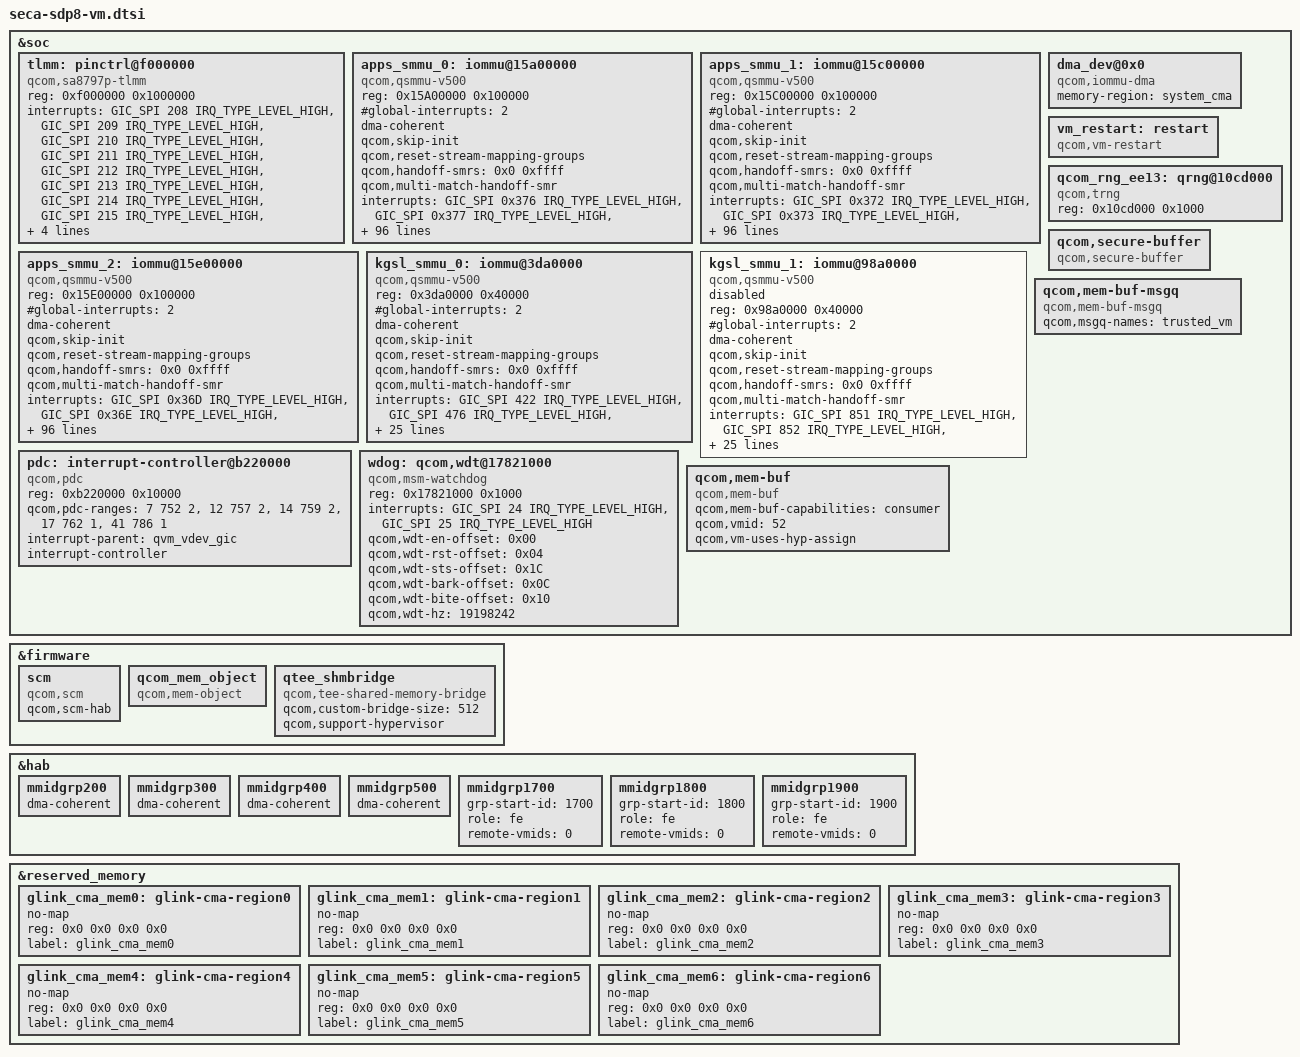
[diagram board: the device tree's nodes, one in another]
// SPDX-License-Identifier: BSD-3-Clause
/*
 * Copyright (c) Qualcomm Technologies, Inc. and/or its subsidiaries.
 */

#include "sdp8-quin-vm-common.dtsi"

&soc {
	tlmm: pinctrl@f000000 {
		compatible = "qcom,sa8797p-tlmm";
		reg = <0xf000000 0x1000000>;
		interrupts = <GIC_SPI 208 IRQ_TYPE_LEVEL_HIGH>,
			<GIC_SPI 209 IRQ_TYPE_LEVEL_HIGH>,
			<GIC_SPI 210 IRQ_TYPE_LEVEL_HIGH>,
			<GIC_SPI 211 IRQ_TYPE_LEVEL_HIGH>,
			<GIC_SPI 212 IRQ_TYPE_LEVEL_HIGH>,
			<GIC_SPI 213 IRQ_TYPE_LEVEL_HIGH>,
			<GIC_SPI 214 IRQ_TYPE_LEVEL_HIGH>,
			<GIC_SPI 215 IRQ_TYPE_LEVEL_HIGH>,
			<GIC_SPI 216 IRQ_TYPE_LEVEL_HIGH>;
		gpio-controller;
		qcom,dirconn-list = <50 GPIO_ACTIVE_HIGH>;
		#gpio-cells = <2>;
		interrupt-controller;
		#interrupt-cells = <2>;
		status = "ok";
	};

	apps_smmu_0: iommu@15a00000 {
		compatible = "qcom,qsmmu-v500";
		reg = <0x15A00000 0x100000>;
		reg-names = "base";
		#iommu-cells = <2>;
		#global-interrupts = <2>;
		dma-coherent;
		qcom,skip-init;
		qcom,reset-stream-mapping-groups;
		qcom,handoff-smrs = <0x0 0xffff>;
		qcom,multi-match-handoff-smr;
		interrupts = <GIC_SPI 0x376 IRQ_TYPE_LEVEL_HIGH>,
				<GIC_SPI 0x377 IRQ_TYPE_LEVEL_HIGH>,
				<GIC_ESPI 0x20 IRQ_TYPE_LEVEL_HIGH>,
				<GIC_ESPI 0x21 IRQ_TYPE_LEVEL_HIGH>,
				<GIC_ESPI 0x22 IRQ_TYPE_LEVEL_HIGH>,
				<GIC_ESPI 0x23 IRQ_TYPE_LEVEL_HIGH>,
				<GIC_ESPI 0x24 IRQ_TYPE_LEVEL_HIGH>,
				<GIC_ESPI 0x25 IRQ_TYPE_LEVEL_HIGH>,
				<GIC_ESPI 0x26 IRQ_TYPE_LEVEL_HIGH>,
				<GIC_ESPI 0x27 IRQ_TYPE_LEVEL_HIGH>,
				<GIC_ESPI 0x28 IRQ_TYPE_LEVEL_HIGH>,
				<GIC_ESPI 0x29 IRQ_TYPE_LEVEL_HIGH>,
				<GIC_ESPI 0x2A IRQ_TYPE_LEVEL_HIGH>,
				<GIC_ESPI 0x2B IRQ_TYPE_LEVEL_HIGH>,
				<GIC_ESPI 0x2C IRQ_TYPE_LEVEL_HIGH>,
				<GIC_ESPI 0x2D IRQ_TYPE_LEVEL_HIGH>,
				<GIC_ESPI 0x2E IRQ_TYPE_LEVEL_HIGH>,
				<GIC_ESPI 0x2F IRQ_TYPE_LEVEL_HIGH>,
				<GIC_ESPI 0x30 IRQ_TYPE_LEVEL_HIGH>,
				<GIC_ESPI 0x31 IRQ_TYPE_LEVEL_HIGH>,
				<GIC_ESPI 0x32 IRQ_TYPE_LEVEL_HIGH>,
				<GIC_ESPI 0x33 IRQ_TYPE_LEVEL_HIGH>,
				<GIC_ESPI 0x34 IRQ_TYPE_LEVEL_HIGH>,
				<GIC_ESPI 0x35 IRQ_TYPE_LEVEL_HIGH>,
				<GIC_ESPI 0x36 IRQ_TYPE_LEVEL_HIGH>,
				<GIC_ESPI 0x37 IRQ_TYPE_LEVEL_HIGH>,
				<GIC_ESPI 0x38 IRQ_TYPE_LEVEL_HIGH>,
				<GIC_ESPI 0x39 IRQ_TYPE_LEVEL_HIGH>,
				<GIC_ESPI 0x3A IRQ_TYPE_LEVEL_HIGH>,
				<GIC_ESPI 0x3B IRQ_TYPE_LEVEL_HIGH>,
				<GIC_ESPI 0x3C IRQ_TYPE_LEVEL_HIGH>,
				<GIC_ESPI 0x3D IRQ_TYPE_LEVEL_HIGH>,
				<GIC_ESPI 0x3E IRQ_TYPE_LEVEL_HIGH>,
				<GIC_ESPI 0x3F IRQ_TYPE_LEVEL_HIGH>,
				<GIC_ESPI 0x40 IRQ_TYPE_LEVEL_HIGH>,
				<GIC_ESPI 0x41 IRQ_TYPE_LEVEL_HIGH>,
				<GIC_ESPI 0x42 IRQ_TYPE_LEVEL_HIGH>,
				<GIC_ESPI 0x43 IRQ_TYPE_LEVEL_HIGH>,
				<GIC_ESPI 0x44 IRQ_TYPE_LEVEL_HIGH>,
				<GIC_ESPI 0x45 IRQ_TYPE_LEVEL_HIGH>,
				<GIC_ESPI 0x46 IRQ_TYPE_LEVEL_HIGH>,
				<GIC_ESPI 0x47 IRQ_TYPE_LEVEL_HIGH>,
				<GIC_ESPI 0x48 IRQ_TYPE_LEVEL_HIGH>,
				<GIC_ESPI 0x49 IRQ_TYPE_LEVEL_HIGH>,
				<GIC_ESPI 0x4A IRQ_TYPE_LEVEL_HIGH>,
				<GIC_ESPI 0x4B IRQ_TYPE_LEVEL_HIGH>,
				<GIC_ESPI 0x4C IRQ_TYPE_LEVEL_HIGH>,
				<GIC_ESPI 0x4D IRQ_TYPE_LEVEL_HIGH>,
				<GIC_ESPI 0x4E IRQ_TYPE_LEVEL_HIGH>,
				<GIC_ESPI 0x4F IRQ_TYPE_LEVEL_HIGH>,
				<GIC_ESPI 0x50 IRQ_TYPE_LEVEL_HIGH>,
				<GIC_ESPI 0x51 IRQ_TYPE_LEVEL_HIGH>,
				<GIC_ESPI 0x52 IRQ_TYPE_LEVEL_HIGH>,
				<GIC_ESPI 0x53 IRQ_TYPE_LEVEL_HIGH>,
				<GIC_ESPI 0x54 IRQ_TYPE_LEVEL_HIGH>,
				<GIC_ESPI 0x55 IRQ_TYPE_LEVEL_HIGH>,
				<GIC_ESPI 0x56 IRQ_TYPE_LEVEL_HIGH>,
				<GIC_ESPI 0x57 IRQ_TYPE_LEVEL_HIGH>,
				<GIC_ESPI 0x58 IRQ_TYPE_LEVEL_HIGH>,
				<GIC_ESPI 0x59 IRQ_TYPE_LEVEL_HIGH>,
				<GIC_ESPI 0x5A IRQ_TYPE_LEVEL_HIGH>,
				<GIC_ESPI 0x5B IRQ_TYPE_LEVEL_HIGH>,
				<GIC_ESPI 0x5C IRQ_TYPE_LEVEL_HIGH>,
				<GIC_ESPI 0x5D IRQ_TYPE_LEVEL_HIGH>,
				<GIC_ESPI 0x5E IRQ_TYPE_LEVEL_HIGH>,
				<GIC_ESPI 0x5F IRQ_TYPE_LEVEL_HIGH>,
				<GIC_ESPI 0x60 IRQ_TYPE_LEVEL_HIGH>,
				<GIC_ESPI 0x61 IRQ_TYPE_LEVEL_HIGH>,
				<GIC_ESPI 0x62 IRQ_TYPE_LEVEL_HIGH>,
				<GIC_ESPI 0x63 IRQ_TYPE_LEVEL_HIGH>,
				<GIC_ESPI 0x64 IRQ_TYPE_LEVEL_HIGH>,
				<GIC_ESPI 0x65 IRQ_TYPE_LEVEL_HIGH>,
				<GIC_ESPI 0x66 IRQ_TYPE_LEVEL_HIGH>,
				<GIC_ESPI 0x67 IRQ_TYPE_LEVEL_HIGH>,
				<GIC_ESPI 0x68 IRQ_TYPE_LEVEL_HIGH>,
				<GIC_ESPI 0x69 IRQ_TYPE_LEVEL_HIGH>,
				<GIC_ESPI 0x6A IRQ_TYPE_LEVEL_HIGH>,
				<GIC_ESPI 0x6B IRQ_TYPE_LEVEL_HIGH>,
				<GIC_ESPI 0x6C IRQ_TYPE_LEVEL_HIGH>,
				<GIC_ESPI 0x6D IRQ_TYPE_LEVEL_HIGH>,
				<GIC_ESPI 0x6E IRQ_TYPE_LEVEL_HIGH>,
				<GIC_ESPI 0x6F IRQ_TYPE_LEVEL_HIGH>,
				<GIC_ESPI 0x70 IRQ_TYPE_LEVEL_HIGH>,
				<GIC_ESPI 0x71 IRQ_TYPE_LEVEL_HIGH>,
				<GIC_ESPI 0x72 IRQ_TYPE_LEVEL_HIGH>,
				<GIC_ESPI 0x73 IRQ_TYPE_LEVEL_HIGH>,
				<GIC_ESPI 0x74 IRQ_TYPE_LEVEL_HIGH>,
				<GIC_ESPI 0x75 IRQ_TYPE_LEVEL_HIGH>,
				<GIC_ESPI 0x76 IRQ_TYPE_LEVEL_HIGH>,
				<GIC_ESPI 0x77 IRQ_TYPE_LEVEL_HIGH>,
				<GIC_ESPI 0x78 IRQ_TYPE_LEVEL_HIGH>,
				<GIC_ESPI 0x79 IRQ_TYPE_LEVEL_HIGH>,
				<GIC_ESPI 0x7A IRQ_TYPE_LEVEL_HIGH>,
				<GIC_ESPI 0x7B IRQ_TYPE_LEVEL_HIGH>,
				<GIC_ESPI 0x7C IRQ_TYPE_LEVEL_HIGH>,
				<GIC_ESPI 0x7D IRQ_TYPE_LEVEL_HIGH>,
				<GIC_ESPI 0x7E IRQ_TYPE_LEVEL_HIGH>,
				<GIC_ESPI 0x7F IRQ_TYPE_LEVEL_HIGH>;
		status = "ok";
	};

	apps_smmu_1: iommu@15c00000 {
		compatible = "qcom,qsmmu-v500";
		reg = <0x15C00000 0x100000>;
		reg-names = "base";
		#iommu-cells = <2>;
		#global-interrupts = <2>;
		dma-coherent;
		qcom,skip-init;
		qcom,reset-stream-mapping-groups;
		qcom,handoff-smrs = <0x0 0xffff>;
		qcom,multi-match-handoff-smr;
		interrupts = <GIC_SPI  0x372 IRQ_TYPE_LEVEL_HIGH>,
				<GIC_SPI  0x373 IRQ_TYPE_LEVEL_HIGH>,
				<GIC_ESPI 0x80 IRQ_TYPE_LEVEL_HIGH>,
				<GIC_ESPI 0x81 IRQ_TYPE_LEVEL_HIGH>,
				<GIC_ESPI 0x82 IRQ_TYPE_LEVEL_HIGH>,
				<GIC_ESPI 0x83 IRQ_TYPE_LEVEL_HIGH>,
				<GIC_ESPI 0x84 IRQ_TYPE_LEVEL_HIGH>,
				<GIC_ESPI 0x85 IRQ_TYPE_LEVEL_HIGH>,
				<GIC_ESPI 0x86 IRQ_TYPE_LEVEL_HIGH>,
				<GIC_ESPI 0x87 IRQ_TYPE_LEVEL_HIGH>,
				<GIC_ESPI 0x88 IRQ_TYPE_LEVEL_HIGH>,
				<GIC_ESPI 0x89 IRQ_TYPE_LEVEL_HIGH>,
				<GIC_ESPI 0x8a IRQ_TYPE_LEVEL_HIGH>,
				<GIC_ESPI 0x8b IRQ_TYPE_LEVEL_HIGH>,
				<GIC_ESPI 0x8c IRQ_TYPE_LEVEL_HIGH>,
				<GIC_ESPI 0x8d IRQ_TYPE_LEVEL_HIGH>,
				<GIC_ESPI 0x8e IRQ_TYPE_LEVEL_HIGH>,
				<GIC_ESPI 0x8f IRQ_TYPE_LEVEL_HIGH>,
				<GIC_ESPI 0x90 IRQ_TYPE_LEVEL_HIGH>,
				<GIC_ESPI 0x91 IRQ_TYPE_LEVEL_HIGH>,
				<GIC_ESPI 0x92 IRQ_TYPE_LEVEL_HIGH>,
				<GIC_ESPI 0x93 IRQ_TYPE_LEVEL_HIGH>,
				<GIC_ESPI 0x94 IRQ_TYPE_LEVEL_HIGH>,
				<GIC_ESPI 0x95 IRQ_TYPE_LEVEL_HIGH>,
				<GIC_ESPI 0x96 IRQ_TYPE_LEVEL_HIGH>,
				<GIC_ESPI 0x97 IRQ_TYPE_LEVEL_HIGH>,
				<GIC_ESPI 0x98 IRQ_TYPE_LEVEL_HIGH>,
				<GIC_ESPI 0x99 IRQ_TYPE_LEVEL_HIGH>,
				<GIC_ESPI 0x9a IRQ_TYPE_LEVEL_HIGH>,
				<GIC_ESPI 0x9b IRQ_TYPE_LEVEL_HIGH>,
				<GIC_ESPI 0x9c IRQ_TYPE_LEVEL_HIGH>,
				<GIC_ESPI 0x9d IRQ_TYPE_LEVEL_HIGH>,
				<GIC_ESPI 0x9e IRQ_TYPE_LEVEL_HIGH>,
				<GIC_ESPI 0x9f IRQ_TYPE_LEVEL_HIGH>,
				<GIC_ESPI 0xa0 IRQ_TYPE_LEVEL_HIGH>,
				<GIC_ESPI 0xa1 IRQ_TYPE_LEVEL_HIGH>,
				<GIC_ESPI 0xa2 IRQ_TYPE_LEVEL_HIGH>,
				<GIC_ESPI 0xa3 IRQ_TYPE_LEVEL_HIGH>,
				<GIC_ESPI 0xa4 IRQ_TYPE_LEVEL_HIGH>,
				<GIC_ESPI 0xa5 IRQ_TYPE_LEVEL_HIGH>,
				<GIC_ESPI 0xa6 IRQ_TYPE_LEVEL_HIGH>,
				<GIC_ESPI 0xa7 IRQ_TYPE_LEVEL_HIGH>,
				<GIC_ESPI 0xa8 IRQ_TYPE_LEVEL_HIGH>,
				<GIC_ESPI 0xa9 IRQ_TYPE_LEVEL_HIGH>,
				<GIC_ESPI 0xaa IRQ_TYPE_LEVEL_HIGH>,
				<GIC_ESPI 0xab IRQ_TYPE_LEVEL_HIGH>,
				<GIC_ESPI 0xac IRQ_TYPE_LEVEL_HIGH>,
				<GIC_ESPI 0xad IRQ_TYPE_LEVEL_HIGH>,
				<GIC_ESPI 0xae IRQ_TYPE_LEVEL_HIGH>,
				<GIC_ESPI 0xaf IRQ_TYPE_LEVEL_HIGH>,
				<GIC_ESPI 0xb0 IRQ_TYPE_LEVEL_HIGH>,
				<GIC_ESPI 0xb1 IRQ_TYPE_LEVEL_HIGH>,
				<GIC_ESPI 0xb2 IRQ_TYPE_LEVEL_HIGH>,
				<GIC_ESPI 0xb3 IRQ_TYPE_LEVEL_HIGH>,
				<GIC_ESPI 0xb4 IRQ_TYPE_LEVEL_HIGH>,
				<GIC_ESPI 0xb5 IRQ_TYPE_LEVEL_HIGH>,
				<GIC_ESPI 0xb6 IRQ_TYPE_LEVEL_HIGH>,
				<GIC_ESPI 0xb7 IRQ_TYPE_LEVEL_HIGH>,
				<GIC_ESPI 0xb8 IRQ_TYPE_LEVEL_HIGH>,
				<GIC_ESPI 0xb9 IRQ_TYPE_LEVEL_HIGH>,
				<GIC_ESPI 0xba IRQ_TYPE_LEVEL_HIGH>,
				<GIC_ESPI 0xbb IRQ_TYPE_LEVEL_HIGH>,
				<GIC_ESPI 0xbc IRQ_TYPE_LEVEL_HIGH>,
				<GIC_ESPI 0xbd IRQ_TYPE_LEVEL_HIGH>,
				<GIC_ESPI 0xbe IRQ_TYPE_LEVEL_HIGH>,
				<GIC_ESPI 0xbf IRQ_TYPE_LEVEL_HIGH>,
				<GIC_ESPI 0xc0 IRQ_TYPE_LEVEL_HIGH>,
				<GIC_ESPI 0xc1 IRQ_TYPE_LEVEL_HIGH>,
				<GIC_ESPI 0xc2 IRQ_TYPE_LEVEL_HIGH>,
				<GIC_ESPI 0xc3 IRQ_TYPE_LEVEL_HIGH>,
				<GIC_ESPI 0xc4 IRQ_TYPE_LEVEL_HIGH>,
				<GIC_ESPI 0xc5 IRQ_TYPE_LEVEL_HIGH>,
				<GIC_ESPI 0xc6 IRQ_TYPE_LEVEL_HIGH>,
				<GIC_ESPI 0xc7 IRQ_TYPE_LEVEL_HIGH>,
				<GIC_ESPI 0xc8 IRQ_TYPE_LEVEL_HIGH>,
				<GIC_ESPI 0xc9 IRQ_TYPE_LEVEL_HIGH>,
				<GIC_ESPI 0xca IRQ_TYPE_LEVEL_HIGH>,
				<GIC_ESPI 0xcb IRQ_TYPE_LEVEL_HIGH>,
				<GIC_ESPI 0xcc IRQ_TYPE_LEVEL_HIGH>,
				<GIC_ESPI 0xcd IRQ_TYPE_LEVEL_HIGH>,
				<GIC_ESPI 0xce IRQ_TYPE_LEVEL_HIGH>,
				<GIC_ESPI 0xcf IRQ_TYPE_LEVEL_HIGH>,
				<GIC_ESPI 0xd0 IRQ_TYPE_LEVEL_HIGH>,
				<GIC_ESPI 0xd1 IRQ_TYPE_LEVEL_HIGH>,
				<GIC_ESPI 0xd2 IRQ_TYPE_LEVEL_HIGH>,
				<GIC_ESPI 0xd3 IRQ_TYPE_LEVEL_HIGH>,
				<GIC_ESPI 0xd4 IRQ_TYPE_LEVEL_HIGH>,
				<GIC_ESPI 0xd5 IRQ_TYPE_LEVEL_HIGH>,
				<GIC_ESPI 0xd6 IRQ_TYPE_LEVEL_HIGH>,
				<GIC_ESPI 0xd7 IRQ_TYPE_LEVEL_HIGH>,
				<GIC_ESPI 0xd8 IRQ_TYPE_LEVEL_HIGH>,
				<GIC_ESPI 0xd9 IRQ_TYPE_LEVEL_HIGH>,
				<GIC_ESPI 0xda IRQ_TYPE_LEVEL_HIGH>,
				<GIC_ESPI 0xdb IRQ_TYPE_LEVEL_HIGH>,
				<GIC_ESPI 0xdc IRQ_TYPE_LEVEL_HIGH>,
				<GIC_ESPI 0xdd IRQ_TYPE_LEVEL_HIGH>,
				<GIC_ESPI 0xde IRQ_TYPE_LEVEL_HIGH>,
				<GIC_ESPI 0xdf IRQ_TYPE_LEVEL_HIGH>;
		status = "ok";
	};

	apps_smmu_2: iommu@15e00000 {
		compatible = "qcom,qsmmu-v500";
		reg = <0x15E00000 0x100000>;
		reg-names = "base";
		#iommu-cells = <2>;
		#global-interrupts = <2>;
		dma-coherent;
		qcom,skip-init;
		qcom,reset-stream-mapping-groups;
		qcom,handoff-smrs = <0x0 0xffff>;
		qcom,multi-match-handoff-smr;
		interrupts = <GIC_SPI  0x36D IRQ_TYPE_LEVEL_HIGH>,
				<GIC_SPI  0x36E IRQ_TYPE_LEVEL_HIGH>,
				<GIC_ESPI 0xe0 IRQ_TYPE_LEVEL_HIGH>,
				<GIC_ESPI 0xe1 IRQ_TYPE_LEVEL_HIGH>,
				<GIC_ESPI 0xe2 IRQ_TYPE_LEVEL_HIGH>,
				<GIC_ESPI 0xe3 IRQ_TYPE_LEVEL_HIGH>,
				<GIC_ESPI 0xe4 IRQ_TYPE_LEVEL_HIGH>,
				<GIC_ESPI 0xe5 IRQ_TYPE_LEVEL_HIGH>,
				<GIC_ESPI 0xe6 IRQ_TYPE_LEVEL_HIGH>,
				<GIC_ESPI 0xe7 IRQ_TYPE_LEVEL_HIGH>,
				<GIC_ESPI 0xe8 IRQ_TYPE_LEVEL_HIGH>,
				<GIC_ESPI 0xe9 IRQ_TYPE_LEVEL_HIGH>,
				<GIC_ESPI 0xea IRQ_TYPE_LEVEL_HIGH>,
				<GIC_ESPI 0xeb IRQ_TYPE_LEVEL_HIGH>,
				<GIC_ESPI 0xec IRQ_TYPE_LEVEL_HIGH>,
				<GIC_ESPI 0xed IRQ_TYPE_LEVEL_HIGH>,
				<GIC_ESPI 0xee IRQ_TYPE_LEVEL_HIGH>,
				<GIC_ESPI 0xef IRQ_TYPE_LEVEL_HIGH>,
				<GIC_ESPI 0xf0 IRQ_TYPE_LEVEL_HIGH>,
				<GIC_ESPI 0xf1 IRQ_TYPE_LEVEL_HIGH>,
				<GIC_ESPI 0xf2 IRQ_TYPE_LEVEL_HIGH>,
				<GIC_ESPI 0xf3 IRQ_TYPE_LEVEL_HIGH>,
				<GIC_ESPI 0xf4 IRQ_TYPE_LEVEL_HIGH>,
				<GIC_ESPI 0xf5 IRQ_TYPE_LEVEL_HIGH>,
				<GIC_ESPI 0xf6 IRQ_TYPE_LEVEL_HIGH>,
				<GIC_ESPI 0xf7 IRQ_TYPE_LEVEL_HIGH>,
				<GIC_ESPI 0xf8 IRQ_TYPE_LEVEL_HIGH>,
				<GIC_ESPI 0xf9 IRQ_TYPE_LEVEL_HIGH>,
				<GIC_ESPI 0xfa IRQ_TYPE_LEVEL_HIGH>,
				<GIC_ESPI 0xfb IRQ_TYPE_LEVEL_HIGH>,
				<GIC_ESPI 0xfc IRQ_TYPE_LEVEL_HIGH>,
				<GIC_ESPI 0xfd IRQ_TYPE_LEVEL_HIGH>,
				<GIC_ESPI 0xfe IRQ_TYPE_LEVEL_HIGH>,
				<GIC_ESPI 0xff IRQ_TYPE_LEVEL_HIGH>,
				<GIC_ESPI 0x100 IRQ_TYPE_LEVEL_HIGH>,
				<GIC_ESPI 0x101 IRQ_TYPE_LEVEL_HIGH>,
				<GIC_ESPI 0x102 IRQ_TYPE_LEVEL_HIGH>,
				<GIC_ESPI 0x103 IRQ_TYPE_LEVEL_HIGH>,
				<GIC_ESPI 0x104 IRQ_TYPE_LEVEL_HIGH>,
				<GIC_ESPI 0x105 IRQ_TYPE_LEVEL_HIGH>,
				<GIC_ESPI 0x106 IRQ_TYPE_LEVEL_HIGH>,
				<GIC_ESPI 0x107 IRQ_TYPE_LEVEL_HIGH>,
				<GIC_ESPI 0x108 IRQ_TYPE_LEVEL_HIGH>,
				<GIC_ESPI 0x109 IRQ_TYPE_LEVEL_HIGH>,
				<GIC_ESPI 0x10a IRQ_TYPE_LEVEL_HIGH>,
				<GIC_ESPI 0x10b IRQ_TYPE_LEVEL_HIGH>,
				<GIC_ESPI 0x10c IRQ_TYPE_LEVEL_HIGH>,
				<GIC_ESPI 0x10d IRQ_TYPE_LEVEL_HIGH>,
				<GIC_ESPI 0x10e IRQ_TYPE_LEVEL_HIGH>,
				<GIC_ESPI 0x10f IRQ_TYPE_LEVEL_HIGH>,
				<GIC_ESPI 0x110 IRQ_TYPE_LEVEL_HIGH>,
				<GIC_ESPI 0x111 IRQ_TYPE_LEVEL_HIGH>,
				<GIC_ESPI 0x112 IRQ_TYPE_LEVEL_HIGH>,
				<GIC_ESPI 0x113 IRQ_TYPE_LEVEL_HIGH>,
				<GIC_ESPI 0x114 IRQ_TYPE_LEVEL_HIGH>,
				<GIC_ESPI 0x115 IRQ_TYPE_LEVEL_HIGH>,
				<GIC_ESPI 0x116 IRQ_TYPE_LEVEL_HIGH>,
				<GIC_ESPI 0x117 IRQ_TYPE_LEVEL_HIGH>,
				<GIC_ESPI 0x118 IRQ_TYPE_LEVEL_HIGH>,
				<GIC_ESPI 0x119 IRQ_TYPE_LEVEL_HIGH>,
				<GIC_ESPI 0x11a IRQ_TYPE_LEVEL_HIGH>,
				<GIC_ESPI 0x11b IRQ_TYPE_LEVEL_HIGH>,
				<GIC_ESPI 0x11c IRQ_TYPE_LEVEL_HIGH>,
				<GIC_ESPI 0x11d IRQ_TYPE_LEVEL_HIGH>,
				<GIC_ESPI 0x11e IRQ_TYPE_LEVEL_HIGH>,
				<GIC_ESPI 0x11f IRQ_TYPE_LEVEL_HIGH>,
				<GIC_ESPI 0x120 IRQ_TYPE_LEVEL_HIGH>,
				<GIC_ESPI 0x121 IRQ_TYPE_LEVEL_HIGH>,
				<GIC_ESPI 0x122 IRQ_TYPE_LEVEL_HIGH>,
				<GIC_ESPI 0x123 IRQ_TYPE_LEVEL_HIGH>,
				<GIC_ESPI 0x124 IRQ_TYPE_LEVEL_HIGH>,
				<GIC_ESPI 0x125 IRQ_TYPE_LEVEL_HIGH>,
				<GIC_ESPI 0x126 IRQ_TYPE_LEVEL_HIGH>,
				<GIC_ESPI 0x127 IRQ_TYPE_LEVEL_HIGH>,
				<GIC_ESPI 0x128 IRQ_TYPE_LEVEL_HIGH>,
				<GIC_ESPI 0x129 IRQ_TYPE_LEVEL_HIGH>,
				<GIC_ESPI 0x12a IRQ_TYPE_LEVEL_HIGH>,
				<GIC_ESPI 0x12b IRQ_TYPE_LEVEL_HIGH>,
				<GIC_ESPI 0x12c IRQ_TYPE_LEVEL_HIGH>,
				<GIC_ESPI 0x12d IRQ_TYPE_LEVEL_HIGH>,
				<GIC_ESPI 0x12e IRQ_TYPE_LEVEL_HIGH>,
				<GIC_ESPI 0x12f IRQ_TYPE_LEVEL_HIGH>,
				<GIC_ESPI 0x130 IRQ_TYPE_LEVEL_HIGH>,
				<GIC_ESPI 0x131 IRQ_TYPE_LEVEL_HIGH>,
				<GIC_ESPI 0x132 IRQ_TYPE_LEVEL_HIGH>,
				<GIC_ESPI 0x133 IRQ_TYPE_LEVEL_HIGH>,
				<GIC_ESPI 0x134 IRQ_TYPE_LEVEL_HIGH>,
				<GIC_ESPI 0x135 IRQ_TYPE_LEVEL_HIGH>,
				<GIC_ESPI 0x136 IRQ_TYPE_LEVEL_HIGH>,
				<GIC_ESPI 0x137 IRQ_TYPE_LEVEL_HIGH>,
				<GIC_ESPI 0x138 IRQ_TYPE_LEVEL_HIGH>,
				<GIC_ESPI 0x139 IRQ_TYPE_LEVEL_HIGH>,
				<GIC_ESPI 0x13a IRQ_TYPE_LEVEL_HIGH>,
				<GIC_ESPI 0x13b IRQ_TYPE_LEVEL_HIGH>,
				<GIC_ESPI 0x13c IRQ_TYPE_LEVEL_HIGH>,
				<GIC_ESPI 0x13d IRQ_TYPE_LEVEL_HIGH>,
				<GIC_ESPI 0x13e IRQ_TYPE_LEVEL_HIGH>,
				<GIC_ESPI 0x13f IRQ_TYPE_LEVEL_HIGH>;
		status = "ok";
	};

	kgsl_smmu_0: iommu@3da0000 {
		compatible = "qcom,qsmmu-v500";
		reg = <0x3da0000 0x40000>;
		reg-names = "base";
		#iommu-cells = <2>;
		#global-interrupts = <2>;
		dma-coherent;
		qcom,skip-init;
		qcom,reset-stream-mapping-groups;
		qcom,handoff-smrs = <0x0 0xffff>;
		qcom,multi-match-handoff-smr;
		interrupts = <GIC_SPI 422 IRQ_TYPE_LEVEL_HIGH>,
				<GIC_SPI 476 IRQ_TYPE_LEVEL_HIGH>,
				<GIC_SPI 574 IRQ_TYPE_LEVEL_HIGH>,
				<GIC_SPI 575 IRQ_TYPE_LEVEL_HIGH>,
				<GIC_SPI 576 IRQ_TYPE_LEVEL_HIGH>,
				<GIC_SPI 577 IRQ_TYPE_LEVEL_HIGH>,
				<GIC_SPI 660 IRQ_TYPE_LEVEL_HIGH>,
				<GIC_SPI 662 IRQ_TYPE_LEVEL_HIGH>,
				<GIC_SPI 665 IRQ_TYPE_LEVEL_HIGH>,
				<GIC_SPI 666 IRQ_TYPE_LEVEL_HIGH>,
				<GIC_SPI 667 IRQ_TYPE_LEVEL_HIGH>,
				<GIC_SPI 669 IRQ_TYPE_LEVEL_HIGH>,
				<GIC_SPI 670 IRQ_TYPE_LEVEL_HIGH>,
				<GIC_SPI 673 IRQ_TYPE_LEVEL_HIGH>,
				<GIC_SPI 674 IRQ_TYPE_LEVEL_HIGH>,
				<GIC_SPI 678 IRQ_TYPE_LEVEL_HIGH>,
				<GIC_SPI 679 IRQ_TYPE_LEVEL_HIGH>,
				<GIC_SPI 680 IRQ_TYPE_LEVEL_HIGH>,
				<GIC_SPI 681 IRQ_TYPE_LEVEL_HIGH>,
				<GIC_SPI 682 IRQ_TYPE_LEVEL_HIGH>,
				<GIC_SPI 683 IRQ_TYPE_LEVEL_HIGH>,
				<GIC_SPI 684 IRQ_TYPE_LEVEL_HIGH>,
				<GIC_SPI 685 IRQ_TYPE_LEVEL_HIGH>,
				<GIC_SPI 686 IRQ_TYPE_LEVEL_HIGH>,
				<GIC_SPI 687 IRQ_TYPE_LEVEL_HIGH>,
				<GIC_SPI 688 IRQ_TYPE_LEVEL_HIGH>,
				<GIC_SPI 700 IRQ_TYPE_LEVEL_HIGH>;
		status = "ok";
	};

	kgsl_smmu_1: iommu@98a0000 {
		compatible = "qcom,qsmmu-v500";
		reg = <0x98a0000 0x40000>;
		reg-names = "base";
		#iommu-cells = <2>;
		#global-interrupts = <2>;
		dma-coherent;
		qcom,skip-init;
		qcom,reset-stream-mapping-groups;
		qcom,handoff-smrs = <0x0 0xffff>;
		qcom,multi-match-handoff-smr;
		interrupts = <GIC_SPI 851 IRQ_TYPE_LEVEL_HIGH>,
				<GIC_SPI 852 IRQ_TYPE_LEVEL_HIGH>,
				<GIC_SPI 853 IRQ_TYPE_LEVEL_HIGH>,
				<GIC_SPI 854 IRQ_TYPE_LEVEL_HIGH>,
				<GIC_SPI 855 IRQ_TYPE_LEVEL_HIGH>,
				<GIC_SPI 856 IRQ_TYPE_LEVEL_HIGH>,
				<GIC_SPI 857 IRQ_TYPE_LEVEL_HIGH>,
				<GIC_SPI 858 IRQ_TYPE_LEVEL_HIGH>,
				<GIC_SPI 859 IRQ_TYPE_LEVEL_HIGH>,
				<GIC_SPI 920 IRQ_TYPE_LEVEL_HIGH>,
				<GIC_SPI 921 IRQ_TYPE_LEVEL_HIGH>,
				<GIC_SPI 922 IRQ_TYPE_LEVEL_HIGH>,
				<GIC_SPI 924 IRQ_TYPE_LEVEL_HIGH>,
				<GIC_SPI 925 IRQ_TYPE_LEVEL_HIGH>,
				<GIC_SPI 926 IRQ_TYPE_LEVEL_HIGH>,
				<GIC_SPI 927 IRQ_TYPE_LEVEL_HIGH>,
				<GIC_SPI 928 IRQ_TYPE_LEVEL_HIGH>,
				<GIC_SPI 929 IRQ_TYPE_LEVEL_HIGH>,
				<GIC_SPI 931 IRQ_TYPE_LEVEL_HIGH>,
				<GIC_SPI 932 IRQ_TYPE_LEVEL_HIGH>,
				<GIC_SPI 936 IRQ_TYPE_LEVEL_HIGH>,
				<GIC_SPI 937 IRQ_TYPE_LEVEL_HIGH>,
				<GIC_SPI 938 IRQ_TYPE_LEVEL_HIGH>,
				<GIC_SPI 939 IRQ_TYPE_LEVEL_HIGH>,
				<GIC_SPI 940 IRQ_TYPE_LEVEL_HIGH>,
				<GIC_SPI 941 IRQ_TYPE_LEVEL_HIGH>,
				<GIC_SPI 942 IRQ_TYPE_LEVEL_HIGH>;
		status = "disabled";
	};

	dma_dev@0x0 {
		compatible = "qcom,iommu-dma";
		memory-region = <&system_cma>;
		status = "ok";
	};

	vm_restart: restart {
		compatible = "qcom,vm-restart";
		status = "ok";
	};

	pdc: interrupt-controller@b220000 {
		compatible = "qcom,pdc";
		reg = <0xb220000 0x10000>;
		qcom,pdc-ranges = <7 752 2>, <12 757 2>, <14 759 2>, <17 762 1>, <41 786 1>;
		#interrupt-cells = <2>;
		interrupt-parent = <&qvm_vdev_gic>;
		interrupt-controller;
		status = "ok";
	};

	qcom_rng_ee13: qrng@10cd000 {
		compatible = "qcom,trng";
		reg = <0x10cd000 0x1000>;
		status = "ok";
	};

	wdog: qcom,wdt@17821000 {
		compatible = "qcom,msm-watchdog";
		reg = <0x17821000 0x1000>;
		reg-names = "wdt-base";
		interrupts = <GIC_SPI 24 IRQ_TYPE_LEVEL_HIGH>,
			<GIC_SPI 25 IRQ_TYPE_LEVEL_HIGH>;
		qcom,wdt-en-offset = <0x00>;
		qcom,wdt-rst-offset = <0x04>;
		qcom,wdt-sts-offset = <0x1C>;
		qcom,wdt-bark-offset = <0x0C>;
		qcom,wdt-bite-offset = <0x10>;
		qcom,wdt-hz = <19198242>;
		status = "ok";
	};

	qcom,secure-buffer {
		compatible = "qcom,secure-buffer";
	};

	qcom,mem-buf {
		compatible = "qcom,mem-buf";
		qcom,mem-buf-capabilities = "consumer";
		qcom,vmid = <52>;
		qcom,vm-uses-hyp-assign;
	};

	qcom,mem-buf-msgq {
		compatible = "qcom,mem-buf-msgq";
		qcom,msgq-names = "trusted_vm";
	};
};

&firmware {
	scm {
		compatible = "qcom,scm", "qcom,scm-v1.1";
		qcom,scm-hab;
	};

	qcom_mem_object {
		compatible = "qcom,mem-object";
	};

	qtee_shmbridge {
		compatible = "qcom,tee-shared-memory-bridge";
		qcom,custom-bridge-size = <512>;
		qcom,support-hypervisor;
	};
};

&hab {
	mmidgrp200: mmidgrp200 {
	    dma-coherent;
	};

	mmidgrp300: mmidgrp300 {
	    dma-coherent;
	};

	mmidgrp400: mmidgrp400 {
	    dma-coherent;
	};

	mmidgrp500: mmidgrp500 {
	    dma-coherent;
	};

	mmidgrp1700: mmidgrp1700 {
	    grp-start-id = <1700>;
	    role = "fe";
	    remote-vmids = <0>;
	};

	mmidgrp1800: mmidgrp1800 {
	    grp-start-id = <1800>;
	    role = "fe";
	    remote-vmids = <0>;
	};

	mmidgrp1900: mmidgrp1900 {
	    grp-start-id = <1900>;
	    role = "fe";
	    remote-vmids = <0>;
	};
};

&reserved_memory {
	glink_cma_mem0: glink-cma-region0 {
		no-map;
		reg = <0x0 0x0 0x0 0x0>;
		label = "glink_cma_mem0";
	};

	glink_cma_mem1: glink-cma-region1 {
		no-map;
		reg = <0x0 0x0 0x0 0x0>;
		label = "glink_cma_mem1";
	};

	glink_cma_mem2: glink-cma-region2 {
		no-map;
		reg = <0x0 0x0 0x0 0x0>;
		label = "glink_cma_mem2";
	};

	glink_cma_mem3: glink-cma-region3 {
		no-map;
		reg = <0x0 0x0 0x0 0x0>;
		label = "glink_cma_mem3";
	};

	glink_cma_mem4: glink-cma-region4 {
		no-map;
		reg = <0x0 0x0 0x0 0x0>;
		label = "glink_cma_mem4";
	};

	glink_cma_mem5: glink-cma-region5 {
		no-map;
		reg = <0x0 0x0 0x0 0x0>;
		label = "glink_cma_mem5";
	};

	glink_cma_mem6: glink-cma-region6 {
		no-map;
		reg = <0x0 0x0 0x0 0x0>;
		label = "glink_cma_mem6";
	};
};

#include "seca-vm-pinctrl.dtsi"
#include "seca-vm-usb.dtsi"
#include "seca-vm-qupv3.dtsi"
#include "seca-sdp8-vm-pcie.dtsi"
